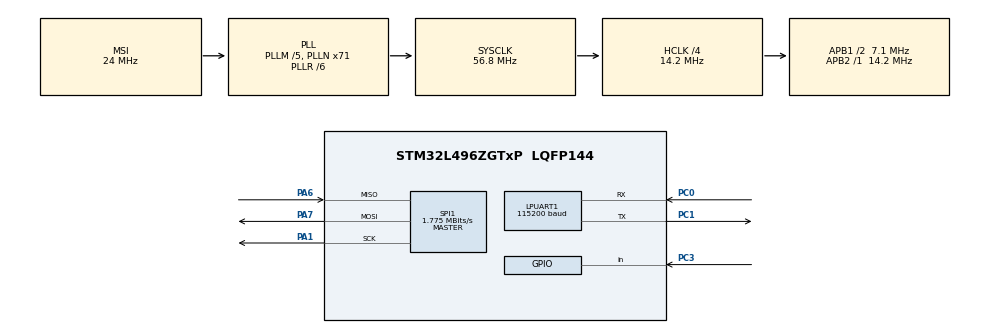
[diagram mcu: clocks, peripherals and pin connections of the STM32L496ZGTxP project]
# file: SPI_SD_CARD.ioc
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FATFS._MAX_SS=4096
FATFS._USE_LFN=1
LPUART1.BaudRate=115200
LPUART1.WordLength=UART_WORDLENGTH_8B
Mcu.Family=STM32L4
Mcu.Name=STM32L496ZGTxP
Mcu.Package=LQFP144
NVIC.PriorityGroup=NVIC_PRIORITYGROUP_4
PA1.Mode=Full_Duplex_Master
PA1.Signal=SPI1_SCK
PA13\ (JTMS/SWDIO).Mode=Serial_Wire
PA13\ (JTMS/SWDIO).Signal=SYS_JTMS-SWDIO
PA14\ (JTCK/SWCLK).Mode=Serial_Wire
PA14\ (JTCK/SWCLK).Signal=SYS_JTCK-SWCLK
PA6.Mode=Full_Duplex_Master
PA6.Signal=SPI1_MISO
PA7.Mode=Full_Duplex_Master
PA7.Signal=SPI1_MOSI
PC0.Mode=Asynchronous
PC0.Signal=LPUART1_RX
PC1.Mode=Asynchronous
PC1.Signal=LPUART1_TX
PC3.Signal=GPIO_Input
PH0-OSC_IN\ (PH0).Mode=HSE-External-Oscillator
PH0-OSC_IN\ (PH0).Signal=RCC_OSC_IN
PH1-OSC_OUT\ (PH1).Mode=HSE-External-Oscillator
PH1-OSC_OUT\ (PH1).Signal=RCC_OSC_OUT
ProjectManager.HeapSize=0x200
ProjectManager.StackSize=0x400
ProjectManager.TargetToolchain=STM32CubeIDE
RCC.48MHZClocksFreq_Value=24000000
RCC.ADCFreq_Value=48000000
RCC.AHBCLKDivider=RCC_SYSCLK_DIV4
RCC.AHBFreq_Value=14200000
RCC.APB1CLKDivider=RCC_HCLK_DIV2
RCC.APB1Freq_Value=7100000
RCC.APB1TimFreq_Value=14200000
RCC.APB2Freq_Value=14200000
RCC.APB2TimFreq_Value=14200000
RCC.CortexFreq_Value=14200000
RCC.HCLKFreq_Value=14200000
RCC.HSE_VALUE=8000000
RCC.HSI48_VALUE=48000000
RCC.HSI_VALUE=16000000
RCC.MSIClockRange=RCC_MSIRANGE_9
RCC.MSI_VALUE=24000000
RCC.PLLM=5
RCC.PLLMUL=RCC_PLL_MUL9
RCC.PLLN=71
RCC.PLLR=RCC_PLLR_DIV6
RCC.PLLSAI1N=20
RCC.PRESCALERUSB=RCC_USBCLKSOURCE_PLL_DIV1_5
RCC.SYSCLKFreq_VALUE=56800000
RCC.SYSCLKSource=RCC_SYSCLKSOURCE_PLLCLK
RCC.SYSCLKSourceVirtual=RCC_SYSCLKSOURCE_PLLCLK
RCC.USBFreq_Value=48000000
RCC.VCOOutputFreq_Value=340800000
SPI1.BaudRatePrescaler=SPI_BAUDRATEPRESCALER_8
SPI1.CalculateBaudRate=1.775 MBits/s
SPI1.Direction=SPI_DIRECTION_2LINES
SPI1.Mode=SPI_MODE_MASTER
SPI1.VirtualType=VM_MASTER
VP_FATFS_VS_Generic.Mode=User_defined
board=NUCLEO-L496ZG-P

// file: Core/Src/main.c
/* USER CODE BEGIN Header */
/**
  ******************************************************************************
  * @file           : main.c
  * @brief          : Main program body
  ******************************************************************************
  * @attention
  *
  * Copyright (c) 2023 STMicroelectronics.
  * All rights reserved.
  *
  * This software is licensed under terms that can be found in the LICENSE file
  * in the root directory of this software component.
  * If no LICENSE file comes with this software, it is provided AS-IS.
  *
  ******************************************************************************
  */
/* USER CODE END Header */
#include "main.h"
#include "fatfs.h"

/* USER CODE BEGIN Includes */
#include "fatfs_sd.h"
#include<string.h>
/* USER CODE END Includes */

/* USER CODE BEGIN PM */
#define SD_CS_GPIO_Port GPIOB
#define SD_CS_Pin GPIO_PIN_0
/* USER CODE END PM */

UART_HandleTypeDef hlpuart1;

SPI_HandleTypeDef hspi1;

void SystemClock_Config(void);
static void MX_GPIO_Init(void);
static void MX_LPUART1_UART_Init(void);
static void MX_SPI1_Init(void);

/* USER CODE BEGIN 0 */
volatile uint8_t FatFsCnt = 0;
volatile uint8_t Timer1, Timer2;

/* USER CODE END 0 */

int main(void)
{

  /* MCU Configuration--------------------------------------------------------*/

  /* Reset of all peripherals, Initializes the Flash interface and the Systick. */
  HAL_Init();

  /* Configure the system clock */
  SystemClock_Config();

  /* Initialize all configured peripherals */
  MX_GPIO_Init();
  MX_LPUART1_UART_Init();
  MX_SPI1_Init();
  MX_FATFS_Init();

  /* Infinite loop */
  while (1)
  {

  }
}

void SystemClock_Config(void)
{
  RCC_OscInitTypeDef RCC_OscInitStruct = {0};
  RCC_ClkInitTypeDef RCC_ClkInitStruct = {0};

  /** Configure the main internal regulator output voltage
  */
  if (HAL_PWREx_ControlVoltageScaling(PWR_REGULATOR_VOLTAGE_SCALE1) != HAL_OK)
  {
    Error_Handler();
  }

  /** Initializes the RCC Oscillators according to the specified parameters
  * in the RCC_OscInitTypeDef structure.
  */
  RCC_OscInitStruct.OscillatorType = RCC_OSCILLATORTYPE_MSI;
  RCC_OscInitStruct.MSIState = RCC_MSI_ON;
  RCC_OscInitStruct.MSICalibrationValue = 0;
  RCC_OscInitStruct.MSIClockRange = RCC_MSIRANGE_9;
  RCC_OscInitStruct.PLL.PLLState = RCC_PLL_ON;
  RCC_OscInitStruct.PLL.PLLSource = RCC_PLLSOURCE_MSI;
  RCC_OscInitStruct.PLL.PLLM = 5;
  RCC_OscInitStruct.PLL.PLLN = 71;
  RCC_OscInitStruct.PLL.PLLP = RCC_PLLP_DIV2;
  RCC_OscInitStruct.PLL.PLLQ = RCC_PLLQ_DIV2;
  RCC_OscInitStruct.PLL.PLLR = RCC_PLLR_DIV6;
  if (HAL_RCC_OscConfig(&RCC_OscInitStruct) != HAL_OK)
  {
    Error_Handler();
  }

  /** Initializes the CPU, AHB and APB buses clocks
  */
  RCC_ClkInitStruct.ClockType = RCC_CLOCKTYPE_HCLK|RCC_CLOCKTYPE_SYSCLK
                              |RCC_CLOCKTYPE_PCLK1|RCC_CLOCKTYPE_PCLK2;
  RCC_ClkInitStruct.SYSCLKSource = RCC_SYSCLKSOURCE_PLLCLK;
  RCC_ClkInitStruct.AHBCLKDivider = RCC_SYSCLK_DIV4;
  RCC_ClkInitStruct.APB1CLKDivider = RCC_HCLK_DIV2;
  RCC_ClkInitStruct.APB2CLKDivider = RCC_HCLK_DIV1;

  if (HAL_RCC_ClockConfig(&RCC_ClkInitStruct, FLASH_LATENCY_0) != HAL_OK)
  {
    Error_Handler();
  }
}

static void MX_LPUART1_UART_Init(void)
{

  hlpuart1.Instance = LPUART1;
  hlpuart1.Init.BaudRate = 115200;
  hlpuart1.Init.WordLength = UART_WORDLENGTH_8B;
  hlpuart1.Init.StopBits = UART_STOPBITS_1;
  hlpuart1.Init.Parity = UART_PARITY_NONE;
  hlpuart1.Init.Mode = UART_MODE_TX_RX;
  hlpuart1.Init.HwFlowCtl = UART_HWCONTROL_NONE;
  hlpuart1.Init.OneBitSampling = UART_ONE_BIT_SAMPLE_DISABLE;
  hlpuart1.AdvancedInit.AdvFeatureInit = UART_ADVFEATURE_NO_INIT;
  if (HAL_UART_Init(&hlpuart1) != HAL_OK)
  {
    Error_Handler();
  }

}

static void MX_SPI1_Init(void)
{

  /* SPI1 parameter configuration*/
  hspi1.Instance = SPI1;
  hspi1.Init.Mode = SPI_MODE_MASTER;
  hspi1.Init.Direction = SPI_DIRECTION_2LINES;
  hspi1.Init.DataSize = SPI_DATASIZE_4BIT;
  hspi1.Init.CLKPolarity = SPI_POLARITY_LOW;
  hspi1.Init.CLKPhase = SPI_PHASE_1EDGE;
  hspi1.Init.NSS = SPI_NSS_SOFT;
  hspi1.Init.BaudRatePrescaler = SPI_BAUDRATEPRESCALER_8;
  hspi1.Init.FirstBit = SPI_FIRSTBIT_MSB;
  hspi1.Init.TIMode = SPI_TIMODE_DISABLE;
  hspi1.Init.CRCCalculation = SPI_CRCCALCULATION_DISABLE;
  hspi1.Init.CRCPolynomial = 7;
  hspi1.Init.CRCLength = SPI_CRC_LENGTH_DATASIZE;
  hspi1.Init.NSSPMode = SPI_NSS_PULSE_ENABLE;
  if (HAL_SPI_Init(&hspi1) != HAL_OK)
  {
    Error_Handler();
  }

}

static void MX_GPIO_Init(void)
{
  GPIO_InitTypeDef GPIO_InitStruct = {0};

  /* GPIO Ports Clock Enable */
  __HAL_RCC_GPIOH_CLK_ENABLE();
  __HAL_RCC_GPIOC_CLK_ENABLE();
  __HAL_RCC_GPIOA_CLK_ENABLE();

  /*Configure GPIO pin : PC3 */
  GPIO_InitStruct.Pin = GPIO_PIN_3;
  GPIO_InitStruct.Mode = GPIO_MODE_INPUT;
  GPIO_InitStruct.Pull = GPIO_NOPULL;
  HAL_GPIO_Init(GPIOC, &GPIO_InitStruct);

}

void Error_Handler(void)
{
  __disable_irq();
  while (1)
  {
  }
}
